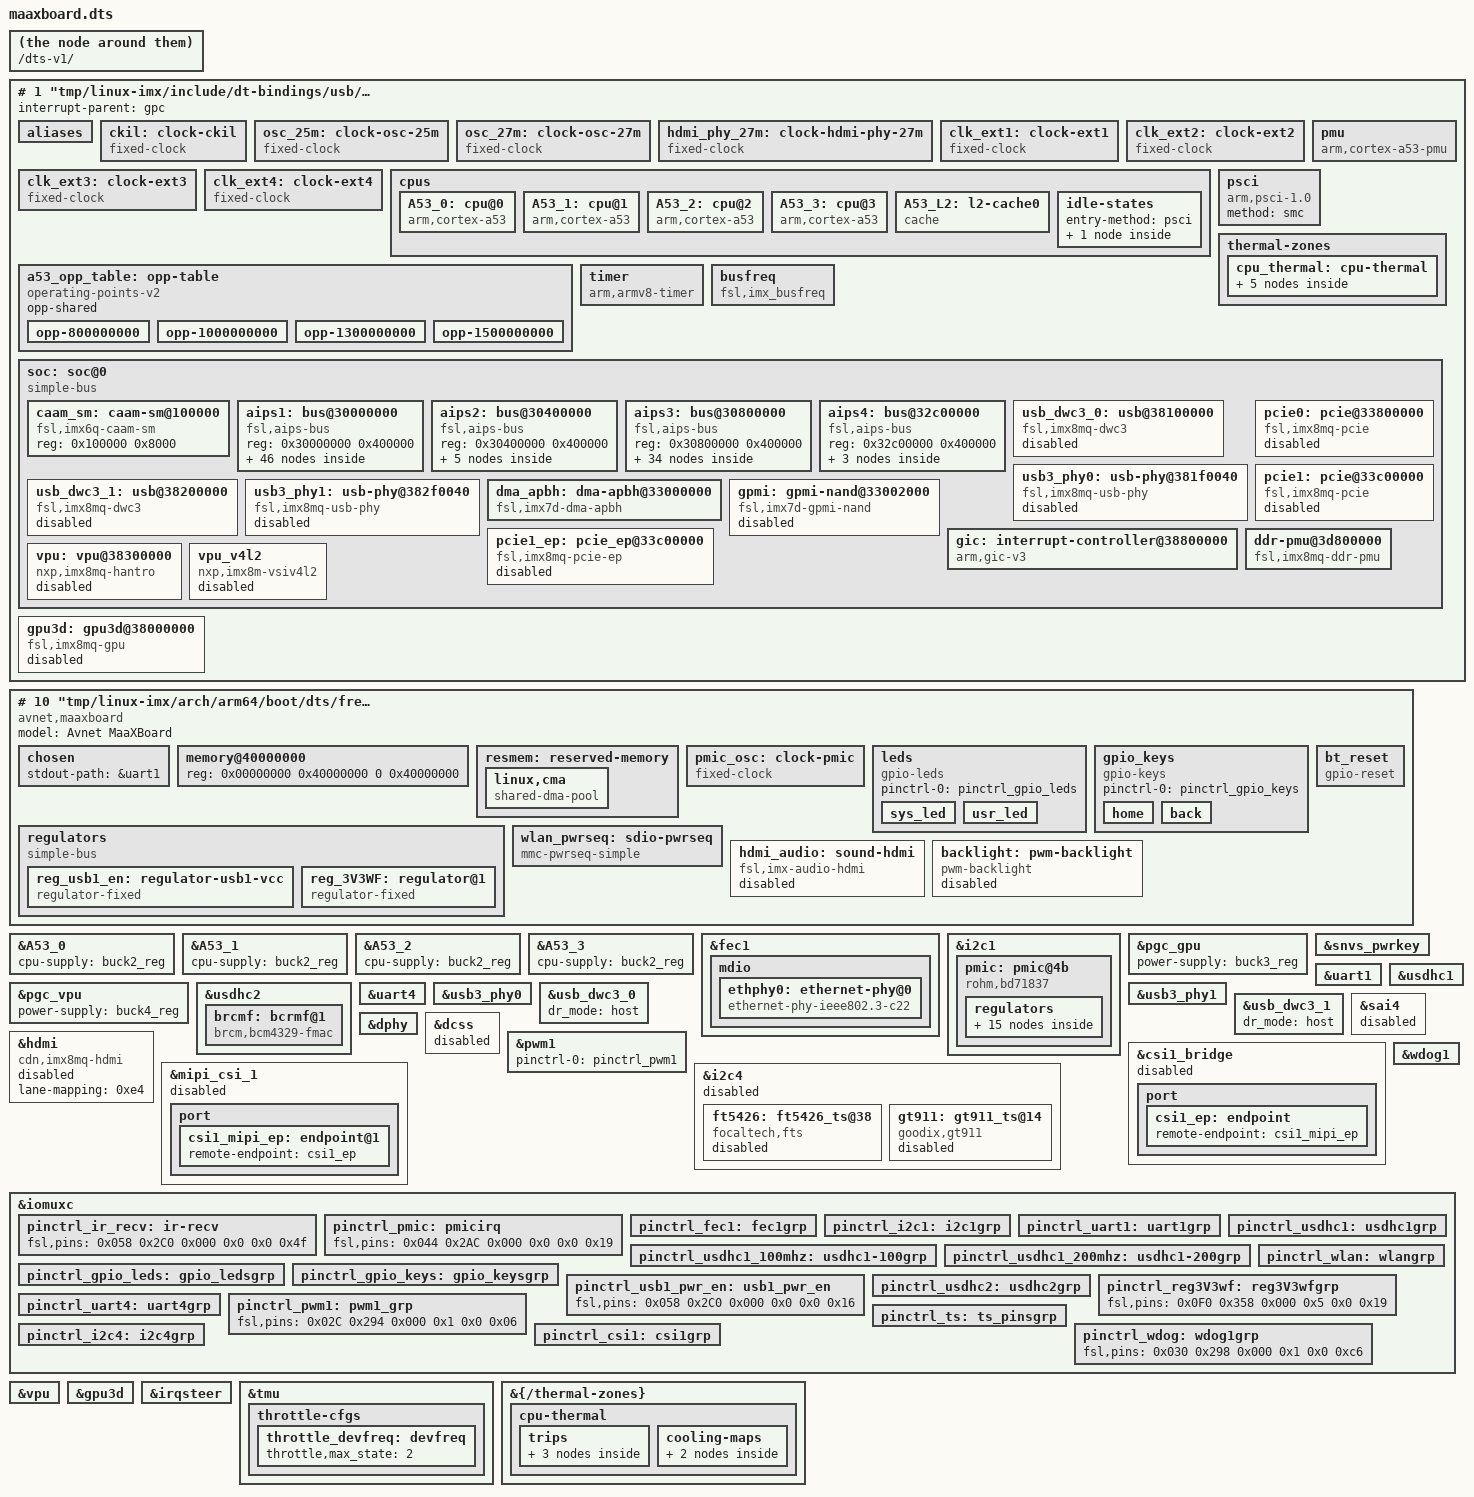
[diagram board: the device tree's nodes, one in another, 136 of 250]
# 0 "tmp/linux-imx/arch/arm64/boot/dts/freescale/maaxboard.dts"
# 0 "<built-in>"
# 0 "<command-line>"
# 1 "tmp/linux-imx/arch/arm64/boot/dts/freescale/maaxboard.dts"





/dts-v1/;

# 1 "tmp/linux-imx/include/dt-bindings/usb/pd.h" 1
# 9 "tmp/linux-imx/arch/arm64/boot/dts/freescale/maaxboard.dts" 2
# 1 "tmp/linux-imx/arch/arm64/boot/dts/freescale/imx8mq.dtsi" 1






# 1 "tmp/linux-imx/include/dt-bindings/clock/imx8mq-clock.h" 1
# 8 "tmp/linux-imx/arch/arm64/boot/dts/freescale/imx8mq.dtsi" 2
# 1 "tmp/linux-imx/include/dt-bindings/power/imx8mq-power.h" 1
# 9 "tmp/linux-imx/arch/arm64/boot/dts/freescale/imx8mq.dtsi" 2
# 1 "tmp/linux-imx/include/dt-bindings/reset/imx8mq-reset.h" 1
# 10 "tmp/linux-imx/arch/arm64/boot/dts/freescale/imx8mq.dtsi" 2
# 1 "tmp/linux-imx/include/dt-bindings/gpio/gpio.h" 1
# 11 "tmp/linux-imx/arch/arm64/boot/dts/freescale/imx8mq.dtsi" 2
# 1 "tmp/linux-imx/include/dt-bindings/input/input.h" 1
# 13 "tmp/linux-imx/include/dt-bindings/input/input.h"
# 1 "tmp/linux-imx/include/dt-bindings/input/linux-event-codes.h" 1
# 14 "tmp/linux-imx/include/dt-bindings/input/input.h" 2
# 12 "tmp/linux-imx/arch/arm64/boot/dts/freescale/imx8mq.dtsi" 2
# 1 "tmp/linux-imx/include/dt-bindings/interrupt-controller/arm-gic.h" 1
# 9 "tmp/linux-imx/include/dt-bindings/interrupt-controller/arm-gic.h"
# 1 "tmp/linux-imx/include/dt-bindings/interrupt-controller/irq.h" 1
# 10 "tmp/linux-imx/include/dt-bindings/interrupt-controller/arm-gic.h" 2
# 13 "tmp/linux-imx/arch/arm64/boot/dts/freescale/imx8mq.dtsi" 2
# 1 "tmp/linux-imx/include/dt-bindings/thermal/thermal.h" 1
# 14 "tmp/linux-imx/arch/arm64/boot/dts/freescale/imx8mq.dtsi" 2
# 1 "tmp/linux-imx/arch/arm64/boot/dts/freescale/imx8mq-pinfunc.h" 1
# 15 "tmp/linux-imx/arch/arm64/boot/dts/freescale/imx8mq.dtsi" 2

/ {
 interrupt-parent = <&gpc>;

 #address-cells = <2>;
 #size-cells = <2>;

 aliases {
  csi0 = &mipi_csi_1;
  csi1 = &mipi_csi_2;
  ethernet0 = &fec1;
  gpio0 = &gpio1;
  gpio1 = &gpio2;
  gpio2 = &gpio3;
  gpio3 = &gpio4;
  gpio4 = &gpio5;
  i2c0 = &i2c1;
  i2c1 = &i2c2;
  i2c2 = &i2c3;
  i2c3 = &i2c4;
  mmc0 = &usdhc1;
  mmc1 = &usdhc2;
  serial0 = &uart1;
  serial1 = &uart2;
  serial2 = &uart3;
  serial3 = &uart4;
  spi0 = &ecspi1;
  spi1 = &ecspi2;
  spi2 = &ecspi3;
 };

 ckil: clock-ckil {
  compatible = "fixed-clock";
  #clock-cells = <0>;
  clock-frequency = <32768>;
  clock-output-names = "ckil";
 };

 osc_25m: clock-osc-25m {
  compatible = "fixed-clock";
  #clock-cells = <0>;
  clock-frequency = <25000000>;
  clock-output-names = "osc_25m";
 };

 osc_27m: clock-osc-27m {
  compatible = "fixed-clock";
  #clock-cells = <0>;
  clock-frequency = <27000000>;
  clock-output-names = "osc_27m";
 };

 hdmi_phy_27m: clock-hdmi-phy-27m {
  compatible = "fixed-clock";
  #clock-cells = <0>;
  clock-frequency = <27000000>;
  clock-output-names = "hdmi_phy_27m";
 };

 clk_ext1: clock-ext1 {
  compatible = "fixed-clock";
  #clock-cells = <0>;
  clock-frequency = <133000000>;
  clock-output-names = "clk_ext1";
 };

 clk_ext2: clock-ext2 {
  compatible = "fixed-clock";
  #clock-cells = <0>;
  clock-frequency = <133000000>;
  clock-output-names = "clk_ext2";
 };

 clk_ext3: clock-ext3 {
  compatible = "fixed-clock";
  #clock-cells = <0>;
  clock-frequency = <133000000>;
  clock-output-names = "clk_ext3";
 };

 clk_ext4: clock-ext4 {
  compatible = "fixed-clock";
  #clock-cells = <0>;
  clock-frequency = <133000000>;
  clock-output-names = "clk_ext4";
 };

 cpus {
  #address-cells = <1>;
  #size-cells = <0>;

  A53_0: cpu@0 {
   device_type = "cpu";
   compatible = "arm,cortex-a53";
   reg = <0x0>;
   clock-latency = <61036>;
   clocks = <&clk 258>;
   enable-method = "psci";
   i-cache-size = <0x8000>;
   i-cache-line-size = <64>;
   i-cache-sets = <256>;
   d-cache-size = <0x8000>;
   d-cache-line-size = <64>;
   d-cache-sets = <128>;
   next-level-cache = <&A53_L2>;
   operating-points-v2 = <&a53_opp_table>;
   #cooling-cells = <2>;
   nvmem-cells = <&cpu_speed_grade>;
   nvmem-cell-names = "speed_grade";
   cpu-idle-states = <&CPU_SLEEP>;
  };

  A53_1: cpu@1 {
   device_type = "cpu";
   compatible = "arm,cortex-a53";
   reg = <0x1>;
   clock-latency = <61036>;
   clocks = <&clk 258>;
   enable-method = "psci";
   i-cache-size = <0x8000>;
   i-cache-line-size = <64>;
   i-cache-sets = <256>;
   d-cache-size = <0x8000>;
   d-cache-line-size = <64>;
   d-cache-sets = <128>;
   next-level-cache = <&A53_L2>;
   operating-points-v2 = <&a53_opp_table>;
   #cooling-cells = <2>;
   cpu-idle-states = <&CPU_SLEEP>;
  };

  A53_2: cpu@2 {
   device_type = "cpu";
   compatible = "arm,cortex-a53";
   reg = <0x2>;
   clock-latency = <61036>;
   clocks = <&clk 258>;
   enable-method = "psci";
   i-cache-size = <0x8000>;
   i-cache-line-size = <64>;
   i-cache-sets = <256>;
   d-cache-size = <0x8000>;
   d-cache-line-size = <64>;
   d-cache-sets = <128>;
   next-level-cache = <&A53_L2>;
   operating-points-v2 = <&a53_opp_table>;
   #cooling-cells = <2>;
   cpu-idle-states = <&CPU_SLEEP>;
  };

  A53_3: cpu@3 {
   device_type = "cpu";
   compatible = "arm,cortex-a53";
   reg = <0x3>;
   clock-latency = <61036>;
   clocks = <&clk 258>;
   enable-method = "psci";
   i-cache-size = <0x8000>;
   i-cache-line-size = <64>;
   i-cache-sets = <256>;
   d-cache-size = <0x8000>;
   d-cache-line-size = <64>;
   d-cache-sets = <128>;
   next-level-cache = <&A53_L2>;
   operating-points-v2 = <&a53_opp_table>;
   #cooling-cells = <2>;
   cpu-idle-states = <&CPU_SLEEP>;
  };

  A53_L2: l2-cache0 {
   compatible = "cache";
   cache-level = <2>;
   cache-size = <0x100000>;
   cache-line-size = <64>;
   cache-sets = <1024>;
  };

  idle-states {
   entry-method = "psci";

   CPU_SLEEP: cpu-sleep {
    compatible = "arm,idle-state";
    arm,psci-suspend-param = <0x0010033>;
    local-timer-stop;
    entry-latency-us = <1000>;
    exit-latency-us = <700>;
    min-residency-us = <2700>;
    wakeup-latency-us = <1500>;
   };
  };

 };

 a53_opp_table: opp-table {
  compatible = "operating-points-v2";
  opp-shared;

  opp-800000000 {
   opp-hz = /bits/ 64 <800000000>;
   opp-microvolt = <900000>;

   opp-supported-hw = <0xf>, <0x4>;
   clock-latency-ns = <150000>;
   opp-suspend;
  };

  opp-1000000000 {
   opp-hz = /bits/ 64 <1000000000>;
   opp-microvolt = <900000>;

   opp-supported-hw = <0xe>, <0x3>;
   clock-latency-ns = <150000>;
   opp-suspend;
  };

  opp-1300000000 {
   opp-hz = /bits/ 64 <1300000000>;
   opp-microvolt = <1000000>;
   opp-supported-hw = <0xc>, <0x4>;
   clock-latency-ns = <150000>;
   opp-suspend;
  };

  opp-1500000000 {
   opp-hz = /bits/ 64 <1500000000>;
   opp-microvolt = <1000000>;
   opp-supported-hw = <0x8>, <0x3>;
   clock-latency-ns = <150000>;
   opp-suspend;
  };
 };

 pmu {
  compatible = "arm,cortex-a53-pmu";
  interrupts = <1 7 4>;
  interrupt-parent = <&gic>;
 };

 psci {
  compatible = "arm,psci-1.0";
  method = "smc";
 };

 thermal-zones {
  cpu_thermal: cpu-thermal {
   polling-delay-passive = <250>;
   polling-delay = <2000>;
   thermal-sensors = <&tmu 0>;

   trips {
    cpu_alert: cpu-alert {
     temperature = <80000>;
     hysteresis = <2000>;
     type = "passive";
    };

    cpu-crit {
     temperature = <90000>;
     hysteresis = <2000>;
     type = "critical";
    };
   };

   cooling-maps {
    map0 {
     trip = <&cpu_alert>;
     cooling-device =
      <&A53_0 (~0) (~0)>,
      <&A53_1 (~0) (~0)>,
      <&A53_2 (~0) (~0)>,
      <&A53_3 (~0) (~0)>;
    };
   };
  };
 };

 timer {
  compatible = "arm,armv8-timer";
  interrupts = <1 13 8>,
               <1 14 8>,
               <1 11 8>,
               <1 10 8>;
  interrupt-parent = <&gic>;
  arm,no-tick-in-suspend;
 };

 busfreq {
  compatible = "fsl,imx_busfreq";
  clocks = <&clk 234>, <&clk 118>,
    <&clk 119>, <&clk 119>,
    <&clk 252>, <&clk 251>,
    <&clk 70>, <&clk 77>,
    <&clk 72>, <&clk 78>,
    <&clk 113>, <&clk 103>,
    <&clk 116>, <&clk 2>,
    <&clk 85>, <&clk 73>;
  clock-names = "dram_pll", "dram_alt_src", "dram_apb_src", "dram_apb_pre_div",
         "dram_core", "dram_alt_root", "sys1_pll_40m", "sys1_pll_400m",
         "sys1_pll_100m", "sys1_pll_800m", "noc_div", "main_axi_src",
         "ahb_div", "osc_25m", "sys2_pll_333m", "sys1_pll_133m";
  interrupts = <0 102 4>, <0 109 4>,
        <0 110 4>, <0 111 4>;
  interrupt-name = "irq_busfreq_0", "irq_busfreq_1", "irq_busfreq_2", "irq_busfreq_3";
 };

 soc: soc@0 {
  compatible = "simple-bus";
  #address-cells = <1>;
  #size-cells = <1>;
  ranges = <0x0 0x0 0x0 0x3e000000>;
  dma-ranges = <0x40000000 0x0 0x40000000 0xc0000000>;
  nvmem-cells = <&imx8mq_uid>;
  nvmem-cell-names = "soc_unique_id";

  caam_sm: caam-sm@100000 {
   compatible = "fsl,imx6q-caam-sm";
   reg = <0x100000 0x8000>;
  };

  aips1: bus@30000000 {
   compatible = "fsl,aips-bus", "simple-bus";
   reg = <0x30000000 0x400000>;
   #address-cells = <1>;
   #size-cells = <1>;
   ranges = <0x30000000 0x30000000 0x400000>;

   sai1: sai@30010000 {
    #sound-dai-cells = <0>;
    compatible = "fsl,imx8mq-sai",
          "fsl,imx6sx-sai";
    reg = <0x30010000 0x10000>;
    interrupts = <0 95 4>;
    clocks = <&clk 238>,
     <&clk 0>,
     <&clk 196>,
     <&clk 0>, <&clk 0>;
    clock-names = "bus", "mclk0", "mclk1", "mclk2", "mclk3";
    dmas = <&sdma2 8 1 0>, <&sdma2 9 1 0>;
    dma-names = "rx", "tx";
    fsl,dataline = <0 0xff 0xff>;
    status = "disabled";
   };

   sai6: sai@30030000 {
    #sound-dai-cells = <0>;
    compatible = "fsl,imx8mq-sai",
          "fsl,imx6sx-sai";
    reg = <0x30030000 0x10000>;
    interrupts = <0 90 4>;
    clocks = <&clk 243>,
     <&clk 0>,
     <&clk 201>,
     <&clk 0>, <&clk 0>;
    clock-names = "bus", "mclk0", "mclk1", "mclk2", "mclk3";
    dmas = <&sdma2 4 24 0>, <&sdma2 5 24 0>;
    dma-names = "rx", "tx";
    fsl,shared-interrupt;
    status = "disabled";
   };

   sai5: sai@30040000 {
    #sound-dai-cells = <0>;
    compatible = "fsl,imx8mq-sai",
          "fsl,imx6sx-sai";
    reg = <0x30040000 0x10000>;
    interrupts = <0 90 4>;
    clocks = <&clk 242>,
     <&clk 0>,
     <&clk 200>,
     <&clk 0>, <&clk 0>;
    clock-names = "bus", "mclk0", "mclk1", "mclk2", "mclk3";
    dmas = <&sdma2 2 24 0>, <&sdma2 3 24 0>;
    dma-names = "rx", "tx";
    fsl,shared-interrupt;
    fsl,dataline = <0 0xf 0xf>;
    status = "disabled";
   };

   sai4: sai@30050000 {
    #sound-dai-cells = <0>;
    compatible = "fsl,imx8mq-sai",
          "fsl,imx6sx-sai";
    reg = <0x30050000 0x10000>;
    interrupts = <0 100 4>;
    clocks = <&clk 241>,
     <&clk 0>,
     <&clk 199>,
     <&clk 0>, <&clk 0>;
    clock-names = "bus", "mclk0", "mclk1", "mclk2", "mclk3";
    dmas = <&sdma2 0 24 0>, <&sdma2 1 24 0>;
    dma-names = "rx", "tx";
    fsl,dataline = <0 0x0 0xf>;
    status = "disabled";
   };

   gpio1: gpio@30200000 {
    compatible = "fsl,imx8mq-gpio", "fsl,imx35-gpio";
    reg = <0x30200000 0x10000>;
    interrupts = <0 64 4>,
                 <0 65 4>;
    clocks = <&clk 259>;
    gpio-controller;
    #gpio-cells = <2>;
    interrupt-controller;
    #interrupt-cells = <2>;
    gpio-ranges = <&iomuxc 0 10 30>;
   };

   gpio2: gpio@30210000 {
    compatible = "fsl,imx8mq-gpio", "fsl,imx35-gpio";
    reg = <0x30210000 0x10000>;
    interrupts = <0 66 4>,
                 <0 67 4>;
    clocks = <&clk 260>;
    gpio-controller;
    #gpio-cells = <2>;
    interrupt-controller;
    #interrupt-cells = <2>;
    gpio-ranges = <&iomuxc 0 40 21>;
   };

   gpio3: gpio@30220000 {
    compatible = "fsl,imx8mq-gpio", "fsl,imx35-gpio";
    reg = <0x30220000 0x10000>;
    interrupts = <0 68 4>,
                 <0 69 4>;
    clocks = <&clk 261>;
    gpio-controller;
    #gpio-cells = <2>;
    interrupt-controller;
    #interrupt-cells = <2>;
    gpio-ranges = <&iomuxc 0 61 26>;
   };

   gpio4: gpio@30230000 {
    compatible = "fsl,imx8mq-gpio", "fsl,imx35-gpio";
    reg = <0x30230000 0x10000>;
    interrupts = <0 70 4>,
                 <0 71 4>;
    clocks = <&clk 262>;
    gpio-controller;
    #gpio-cells = <2>;
    interrupt-controller;
    #interrupt-cells = <2>;
    gpio-ranges = <&iomuxc 0 87 32>;
   };

   gpio5: gpio@30240000 {
    compatible = "fsl,imx8mq-gpio", "fsl,imx35-gpio";
    reg = <0x30240000 0x10000>;
    interrupts = <0 72 4>,
                 <0 73 4>;
    clocks = <&clk 263>;
    gpio-controller;
    #gpio-cells = <2>;
    interrupt-controller;
    #interrupt-cells = <2>;
    gpio-ranges = <&iomuxc 0 119 30>;
   };

   tmu: tmu@30260000 {
    compatible = "fsl,imx8mq-tmu";
    reg = <0x30260000 0x10000>;
    interrupts = <0 49 4>;
    clocks = <&clk 246>;
    little-endian;
    fsl,tmu-range = <0xb0000 0xa0026 0x80048 0x70061>;
    fsl,tmu-calibration = <0x00000000 0x00000023>,
            <0x00000001 0x00000029>,
            <0x00000002 0x0000002f>,
            <0x00000003 0x00000035>,
            <0x00000004 0x0000003d>,
            <0x00000005 0x00000043>,
            <0x00000006 0x0000004b>,
            <0x00000007 0x00000051>,
            <0x00000008 0x00000057>,
            <0x00000009 0x0000005f>,
            <0x0000000a 0x00000067>,
            <0x0000000b 0x0000006f>,

            <0x00010000 0x0000001b>,
            <0x00010001 0x00000023>,
            <0x00010002 0x0000002b>,
            <0x00010003 0x00000033>,
            <0x00010004 0x0000003b>,
            <0x00010005 0x00000043>,
            <0x00010006 0x0000004b>,
            <0x00010007 0x00000055>,
            <0x00010008 0x0000005d>,
            <0x00010009 0x00000067>,
            <0x0001000a 0x00000070>,

            <0x00020000 0x00000017>,
            <0x00020001 0x00000023>,
            <0x00020002 0x0000002d>,
            <0x00020003 0x00000037>,
            <0x00020004 0x00000041>,
            <0x00020005 0x0000004b>,
            <0x00020006 0x00000057>,
            <0x00020007 0x00000063>,
            <0x00020008 0x0000006f>,

            <0x00030000 0x00000015>,
            <0x00030001 0x00000021>,
            <0x00030002 0x0000002d>,
            <0x00030003 0x00000039>,
            <0x00030004 0x00000045>,
            <0x00030005 0x00000053>,
            <0x00030006 0x0000005f>,
            <0x00030007 0x00000071>;
    #thermal-sensor-cells = <1>;
   };

   wdog1: watchdog@30280000 {
    compatible = "fsl,imx8mq-wdt", "fsl,imx21-wdt";
    reg = <0x30280000 0x10000>;
    interrupts = <0 78 4>;
    clocks = <&clk 212>;
    status = "disabled";
   };

   wdog2: watchdog@30290000 {
    compatible = "fsl,imx8mq-wdt", "fsl,imx21-wdt";
    reg = <0x30290000 0x10000>;
    interrupts = <0 79 4>;
    clocks = <&clk 213>;
    status = "disabled";
   };

   wdog3: watchdog@302a0000 {
    compatible = "fsl,imx8mq-wdt", "fsl,imx21-wdt";
    reg = <0x302a0000 0x10000>;
    interrupts = <0 10 4>;
    clocks = <&clk 214>;
    status = "disabled";
   };

   sdma2: dma-controller@302c0000 {
    compatible = "fsl,imx8mq-sdma","fsl,imx7d-sdma";
    reg = <0x302c0000 0x10000>;
    interrupts = <0 103 4>;
    clocks = <&clk 228>,
      <&clk 228>;
    clock-names = "ipg", "ahb";
    #dma-cells = <3>;
    fsl,sdma-ram-script-name = "imx/sdma/sdma-imx7d.bin";
   };

   lcdif: lcd-controller@30320000 {
    compatible = "fsl,imx8mq-lcdif", "fsl,imx28-lcdif";
    reg = <0x30320000 0x10000>;
    interrupts = <0 5 4>;
    clocks = <&clk 128>;
    clock-names = "pix";
    assigned-clocks = <&clk 33>,
        <&clk 36>,
        <&clk 128>,
        <&clk 35>;
    assigned-clock-parents = <&clk 2>,
        <&clk 35>,
        <&clk 37>;
    assigned-clock-rates = <0>, <0>, <0>, <594000000>;
    status = "disabled";

    port {
     lcdif_mipi_dsi: endpoint {
      remote-endpoint = <&mipi_dsi_lcdif_in>;
     };
    };
   };

   iomuxc: pinctrl@30330000 {
    compatible = "fsl,imx8mq-iomuxc";
    reg = <0x30330000 0x10000>;
   };

   iomuxc_gpr: syscon@30340000 {
    compatible = "fsl,imx8mq-iomuxc-gpr", "fsl,imx6q-iomuxc-gpr",
          "syscon", "simple-mfd";
    reg = <0x30340000 0x10000>;

    mux: mux-controller {
     compatible = "mmio-mux";
     #mux-control-cells = <1>;
     mux-reg-masks = <0x34 0x00000004>;
    };
   };

   ocotp: efuse@30350000 {
    compatible = "fsl,imx8mq-ocotp", "syscon", "simple-mfd";
    reg = <0x30350000 0x10000>;
    clocks = <&clk 250>;
    #address-cells = <1>;
    #size-cells = <1>;

    imx8mq_uid: soc-uid@4 {
     reg = <0x4 0x8>;
    };

    cpu_speed_grade: speed-grade@10 {
     reg = <0x10 4>;
    };

    fec_mac_address: mac-address@90 {
     reg = <0x90 6>;
    };

    imx8mq_soc: imx8mq-soc {
     compatible = "fsl,imx8mq-soc";
     nvmem-cells = <&imx8mq_uid>;
     nvmem-cell-names = "soc_unique_id";
    };
   };

   anatop: syscon@30360000 {
    compatible = "fsl,imx8mq-anatop", "syscon";
    reg = <0x30360000 0x10000>;
    interrupts = <0 49 4>;
   };

   irq_sec_vio: caam_secvio {
    compatible = "fsl,imx6q-caam-secvio";
    interrupts = <0 20 4>;
    jtag-tamper = "disabled";
    watchdog-tamper = "enabled";
    internal-boot-tamper = "enabled";
    external-pin-tamper = "disabled";
   };

   caam_snvs: caam-snvs@30370000 {
    compatible = "fsl,imx6q-caam-snvs";
    reg = <0x30370000 0x10000>;
    clocks = <&clk 264>;
    clock-names = "ipg";
   };

   snvs: snvs@30370000 {
    compatible = "fsl,sec-v4.0-mon", "syscon", "simple-mfd";
    reg = <0x30370000 0x10000>;

    snvs_rtc: snvs-rtc-lp{
     compatible = "fsl,sec-v4.0-mon-rtc-lp";
     regmap =<&snvs>;
     offset = <0x34>;
     interrupts = <0 19 4>,
      <0 20 4>;
     clocks = <&clk 264>;
     clock-names = "snvs-rtc";
    };

    snvs_pwrkey: snvs-powerkey {
     compatible = "fsl,sec-v4.0-pwrkey";
     regmap = <&snvs>;
     interrupts = <0 4 4>;
     clocks = <&clk 264>;
     clock-names = "snvs-pwrkey";
     linux,keycode = <116>;
     wakeup-source;
     status = "disabled";
    };
   };

   clk: clock-controller@30380000 {
    compatible = "fsl,imx8mq-ccm";
    reg = <0x30380000 0x10000>;
    interrupts = <0 85 4>,
                 <0 86 4>;
    #clock-cells = <1>;
    clocks = <&ckil>, <&osc_25m>, <&osc_27m>,
             <&clk_ext1>, <&clk_ext2>,
             <&clk_ext3>, <&clk_ext4>;
    clock-names = "ckil", "osc_25m", "osc_27m",
                  "clk_ext1", "clk_ext2",
                  "clk_ext3", "clk_ext4";
    assigned-clocks = <&clk 88>,
        <&clk 289>,
        <&clk 113>,
        <&clk 117>,
        <&clk 26>,
        <&clk 31>,
        <&clk 25>,
        <&clk 30>,
        <&clk 105>;
    assigned-clock-rates = <0>, <0>,
             <800000000>,
             <0>,
             <0>,
             <0>,
             <786432000>,
             <722534400>,
             <0>;
    assigned-clock-parents = <&clk 78>,
        <&clk 12>,
        <&clk 78>,
        <&clk 86>,
        <&clk 25>,
        <&clk 30>,
        <0>,
               <0>,
        <&clk 76>;
   };

   src: reset-controller@30390000 {
    compatible = "fsl,imx8mq-src", "syscon";
    reg = <0x30390000 0x10000>;
    interrupts = <0 89 4>;
    #reset-cells = <1>;
   };

   gpc: gpc@303a0000 {
    compatible = "fsl,imx8mq-gpc";
    reg = <0x303a0000 0x10000>;
    interrupts = <0 87 4>;
    interrupt-parent = <&gic>;
    interrupt-controller;
    broken-wake-request-signals;
    #interrupt-cells = <3>;

    pgc {
     #address-cells = <1>;
     #size-cells = <0>;

     pgc_mipi: power-domain@0 {
      #power-domain-cells = <0>;
      reg = <0>;
     };
# 757 "tmp/linux-imx/arch/arm64/boot/dts/freescale/imx8mq.dtsi"
     pgc_pcie: power-domain@1 {
      #power-domain-cells = <0>;
      reg = <1>;
      power-domains = <&pgc_pcie2>;
     };

     pgc_otg1: power-domain@2 {
      #power-domain-cells = <0>;
      reg = <2>;
     };

     pgc_otg2: power-domain@3 {
      #power-domain-cells = <0>;
      reg = <3>;
     };

     pgc_ddr1: power-domain@4 {
      #power-domain-cells = <0>;
      reg = <4>;
     };

     pgc_gpu: power-domain@5 {
      #power-domain-cells = <0>;
      reg = <5>;
      clocks = <&clk 215>,
               <&clk 102>,
        <&clk 111>,
               <&clk 112>;
     };

     pgc_vpu: power-domain@6 {
      #power-domain-cells = <0>;
      reg = <6>;
      clocks = <&clk 223>,
        <&clk 229>,
        <&clk 230>;
      assigned-clocks = <&clk 120>,
          <&clk 121>,
          <&clk 106>,
          <&clk 21>;
      assigned-clock-parents = <&clk 22>,
          <&clk 22>,
          <&clk 78>,
          <&clk 20>;
      assigned-clock-rates = <600000000>,
               <600000000>,
               <800000000>,
               <0>;
     };

     pgc_disp: power-domain@7 {
      #power-domain-cells = <0>;
      reg = <7>;
     };

     pgc_mipi_csi1: power-domain@8 {
      #power-domain-cells = <0>;
      reg = <8>;
     };

     pgc_mipi_csi2: power-domain@9 {
      #power-domain-cells = <0>;
      reg = <9>;
     };

     pgc_pcie2: power-domain@a {
      #power-domain-cells = <0>;
      reg = <10>;
     };
    };
   };
  };

  aips2: bus@30400000 {
   compatible = "fsl,aips-bus", "simple-bus";
   reg = <0x30400000 0x400000>;
   #address-cells = <1>;
   #size-cells = <1>;
   ranges = <0x30400000 0x30400000 0x400000>;

   pwm1: pwm@30660000 {
    compatible = "fsl,imx8mq-pwm", "fsl,imx27-pwm";
    reg = <0x30660000 0x10000>;
    interrupts = <0 81 4>;
    clocks = <&clk 191>,
             <&clk 191>;
    clock-names = "ipg", "per";
    #pwm-cells = <3>;
    status = "disabled";
   };

   pwm2: pwm@30670000 {
    compatible = "fsl,imx8mq-pwm", "fsl,imx27-pwm";
    reg = <0x30670000 0x10000>;
    interrupts = <0 82 4>;
    clocks = <&clk 192>,
             <&clk 192>;
    clock-names = "ipg", "per";
    #pwm-cells = <3>;
    status = "disabled";
   };

   pwm3: pwm@30680000 {
    compatible = "fsl,imx8mq-pwm", "fsl,imx27-pwm";
    reg = <0x30680000 0x10000>;
    interrupts = <0 83 4>;
    clocks = <&clk 193>,
             <&clk 193>;
    clock-names = "ipg", "per";
    #pwm-cells = <3>;
    status = "disabled";
   };

   pwm4: pwm@30690000 {
    compatible = "fsl,imx8mq-pwm", "fsl,imx27-pwm";
    reg = <0x30690000 0x10000>;
    interrupts = <0 84 4>;
    clocks = <&clk 194>,
             <&clk 194>;
    clock-names = "ipg", "per";
    #pwm-cells = <3>;
    status = "disabled";
   };

   system_counter: timer@306a0000 {
    compatible = "nxp,sysctr-timer";
    reg = <0x306a0000 0x20000>;
    interrupts = <0 47 4>;
    clocks = <&osc_25m>;
    clock-names = "per";
   };
  };

  aips3: bus@30800000 {
   compatible = "fsl,aips-bus", "simple-bus";
   reg = <0x30800000 0x400000>;
   #address-cells = <1>;
   #size-cells = <1>;
   ranges = <0x30800000 0x30800000 0x400000>,
     <0x08000000 0x08000000 0x10000000>;

   spdif1: spdif@30810000 {
    compatible = "fsl,imx8mm-spdif", "fsl,imx35-spdif";
    reg = <0x30810000 0x10000>;
    interrupts = <0 6 4>;
    clocks = <&clk 236>,
     <&clk 2>,
     <&clk 135>,
     <&clk 0>,
     <&clk 0>,
     <&clk 0>,
     <&clk 236>,
     <&clk 0>,
     <&clk 0>,
     <&clk 0>;
    clock-names = "core", "rxtx0",
           "rxtx1", "rxtx2",
           "rxtx3", "rxtx4",
           "rxtx5", "rxtx6",
           "rxtx7", "spba";
    dmas = <&sdma1 8 18 0>, <&sdma1 9 18 0>;
    dma-names = "rx", "tx";
    status = "disabled";
   };

   ecspi1: spi@30820000 {
    #address-cells = <1>;
    #size-cells = <0>;
    compatible = "fsl,imx8mq-ecspi", "fsl,imx51-ecspi";
    reg = <0x30820000 0x10000>;
    interrupts = <0 31 4>;
    clocks = <&clk 179>,
      <&clk 179>;
    clock-names = "ipg", "per";
    dmas = <&sdma1 0 7 1>, <&sdma1 1 7 2>;
    dma-names = "rx", "tx";
    status = "disabled";
   };

   ecspi2: spi@30830000 {
    #address-cells = <1>;
    #size-cells = <0>;
    compatible = "fsl,imx8mq-ecspi", "fsl,imx51-ecspi";
    reg = <0x30830000 0x10000>;
    interrupts = <0 32 4>;
    clocks = <&clk 180>,
      <&clk 180>;
    clock-names = "ipg", "per";
    dmas = <&sdma1 2 7 1>, <&sdma1 3 7 2>;
    dma-names = "rx", "tx";
    status = "disabled";
   };

   ecspi3: spi@30840000 {
    #address-cells = <1>;
    #size-cells = <0>;
    compatible = "fsl,imx8mq-ecspi", "fsl,imx51-ecspi";
    reg = <0x30840000 0x10000>;
    interrupts = <0 33 4>;
    clocks = <&clk 181>,
      <&clk 181>;
    clock-names = "ipg", "per";
    dmas = <&sdma1 4 7 1>, <&sdma1 5 7 2>;
    dma-names = "rx", "tx";
    status = "disabled";
   };

   uart1: serial@30860000 {
    compatible = "fsl,imx8mq-uart",
                 "fsl,imx6q-uart";
    reg = <0x30860000 0x10000>;
    interrupts = <0 26 4>;
    clocks = <&clk 202>,
             <&clk 202>;
    clock-names = "ipg", "per";
    status = "disabled";
   };

   uart3: serial@30880000 {
    compatible = "fsl,imx8mq-uart",
                 "fsl,imx6q-uart";
    reg = <0x30880000 0x10000>;
    interrupts = <0 28 4>;
    clocks = <&clk 204>,
             <&clk 204>;
    clock-names = "ipg", "per";
    dmas = <&sdma1 26 4 0>, <&sdma1 27 4 0>;
    dma-names = "rx", "tx";
    status = "disabled";
   };

   uart2: serial@30890000 {
    compatible = "fsl,imx8mq-uart",
                 "fsl,imx6q-uart";
    reg = <0x30890000 0x10000>;
    interrupts = <0 27 4>;
    clocks = <&clk 203>,
             <&clk 203>;
    clock-names = "ipg", "per";
    dmas = <&sdma1 24 4 0>, <&sdma1 25 4 0>;
    dma-names = "rx", "tx";
    status = "disabled";
   };

   spdif2: spdif@308a0000 {
    compatible = "fsl,imx8mm-spdif", "fsl,imx35-spdif";
    reg = <0x308a0000 0x10000>;
    interrupts = <0 13 4>;
    clocks = <&clk 236>,
     <&clk 2>,
     <&clk 136>,
     <&clk 0>,
     <&clk 0>,
     <&clk 0>,
     <&clk 236>,
     <&clk 0>,
     <&clk 0>,
     <&clk 0>;
    clock-names = "core", "rxtx0",
           "rxtx1", "rxtx2",
           "rxtx3", "rxtx4",
           "rxtx5", "rxtx6",
           "rxtx7", "spba";
    dmas = <&sdma1 16 18 0>, <&sdma1 17 18 0>;
    dma-names = "rx", "tx";
    status = "disabled";
   };

   sai2: sai@308b0000 {
    #sound-dai-cells = <0>;
    compatible = "fsl,imx8mq-sai";
    reg = <0x308b0000 0x10000>;
    interrupts = <0 96 4>;
    clocks = <&clk 239>,
      <&clk 0>,
      <&clk 197>,
      <&clk 0>, <&clk 0>;
    clock-names = "bus", "mclk0", "mclk1", "mclk2", "mclk3";
    dmas = <&sdma1 10 24 0>, <&sdma1 11 24 0>;
    dma-names = "rx", "tx";
    status = "disabled";
   };

   sai3: sai@308c0000 {
    #sound-dai-cells = <0>;
    compatible = "fsl,imx8mq-sai",
          "fsl,imx6sx-sai";
    reg = <0x308c0000 0x10000>;
    interrupts = <0 50 4>;
    clocks = <&clk 240>,
     <&clk 0>,
     <&clk 198>,
     <&clk 0>, <&clk 0>;
    clock-names = "bus", "mclk0", "mclk1", "mclk2", "mclk3";
    dmas = <&sdma1 12 24 0>, <&sdma1 13 24 0>;
    dma-names = "rx", "tx";
    status = "disabled";
   };

   crypto: crypto@30900000 {
    compatible = "fsl,sec-v4.0";
    #address-cells = <1>;
    #size-cells = <1>;
    reg = <0x30900000 0x40000>;
    ranges = <0 0x30900000 0x40000>;
    interrupts = <0 91 4>;
    clocks = <&clk 116>,
      <&clk 236>;
    clock-names = "aclk", "ipg";

    sec_jr0: jr@1000 {
     compatible = "fsl,sec-v4.0-job-ring";
     reg = <0x1000 0x1000>;
     interrupts = <0 105 4>;
     status = "disabled";
    };

    sec_jr1: jr@2000 {
     compatible = "fsl,sec-v4.0-job-ring";
     reg = <0x2000 0x1000>;
     interrupts = <0 106 4>;
    };

    sec_jr2: jr@3000 {
     compatible = "fsl,sec-v4.0-job-ring";
     reg = <0x3000 0x1000>;
     interrupts = <0 114 4>;
    };
   };

   mipi_dsi: mipi-dsi@30a00000 {
    compatible = "fsl,imx8mq-nwl-dsi";
    reg = <0x30a00000 0x300>;
    clocks = <&clk 163>,
      <&clk 244>,
      <&clk 245>,
      <&clk 164>,
      <&clk 35>,
      <&clk 128>;
    clock-names = "core", "rx_esc", "tx_esc", "phy_ref", "video_pll", "lcdif";
    assigned-clocks = <&clk 164>,
        <&clk 163>,
        <&clk 244>,
        <&clk 245>;
    assigned-clock-parents = <&clk 37>,
        <&clk 76>,
        <&clk 71>;
    assigned-clock-rates = <27000000>,
             <266000000>,
             <80000000>,
             <20000000>;
    interrupts = <0 34 4>;
    mux-controls = <&mux 0>;
    power-domains = <&pgc_mipi>;
    phys = <&dphy>;
    phy-names = "dphy";
    resets = <&src 21>,
      <&src 23>,
      <&src 24>,
      <&src 25>;
    reset-names = "byte", "dpi", "esc", "pclk";
    status = "disabled";

    ports {
     #address-cells = <1>;
     #size-cells = <0>;

     port@0 {
      reg = <0>;
      #address-cells = <1>;
      #size-cells = <0>;
      mipi_dsi_lcdif_in: endpoint@0 {
       reg = <0>;
       remote-endpoint = <&lcdif_mipi_dsi>;
      };
     };
    };
   };

   dphy: dphy@30a00300 {
    compatible = "fsl,imx8mq-mipi-dphy";
    reg = <0x30a00300 0x100>;
    clocks = <&clk 164>;
    clock-names = "phy_ref";
    assigned-clocks = <&clk 33>,
        <&clk 36>,
        <&clk 164>,
        <&clk 35>;
    assigned-clock-parents = <&clk 2>,
        <&clk 35>,
        <&clk 37>;
    assigned-clock-rates = <0>, <0>, <24000000>, <594000000>;
    #phy-cells = <0>;
    power-domains = <&pgc_mipi>;
    status = "disabled";
   };

   i2c1: i2c@30a20000 {
    compatible = "fsl,imx8mq-i2c", "fsl,imx21-i2c";
    reg = <0x30a20000 0x10000>;
    interrupts = <0 35 4>;
    clocks = <&clk 184>;
    #address-cells = <1>;
    #size-cells = <0>;
    status = "disabled";
   };

   i2c2: i2c@30a30000 {
    compatible = "fsl,imx8mq-i2c", "fsl,imx21-i2c";
    reg = <0x30a30000 0x10000>;
    interrupts = <0 36 4>;
    clocks = <&clk 185>;
    #address-cells = <1>;
    #size-cells = <0>;
    status = "disabled";
   };

   i2c3: i2c@30a40000 {
    compatible = "fsl,imx8mq-i2c", "fsl,imx21-i2c";
    reg = <0x30a40000 0x10000>;
    interrupts = <0 37 4>;
    clocks = <&clk 186>;
    #address-cells = <1>;
    #size-cells = <0>;
    status = "disabled";
   };

   i2c4: i2c@30a50000 {
    compatible = "fsl,imx8mq-i2c", "fsl,imx21-i2c";
    reg = <0x30a50000 0x10000>;
    interrupts = <0 38 4>;
    clocks = <&clk 187>;
    #address-cells = <1>;
    #size-cells = <0>;
    status = "disabled";
   };

   uart4: serial@30a60000 {
    compatible = "fsl,imx8mq-uart",
                 "fsl,imx6q-uart";
    reg = <0x30a60000 0x10000>;
    interrupts = <0 29 4>;
    clocks = <&clk 205>,
             <&clk 205>;
    clock-names = "ipg", "per";
    dmas = <&sdma1 28 4 0>, <&sdma1 29 4 0>;
    dma-names = "rx", "tx";
    status = "disabled";
   };

   mipi_csi_1: mipi_csi1@30a70000 {
    compatible = "fsl,mxc-mipi-csi2_yav";
    reg = <0x30a70000 0x1000>;
    interrupts = <0 44 4>;
    clocks = <&clk 167>,
      <&clk 169>,
      <&clk 168>;
    clock-names = "clk_core", "clk_esc", "clk_pxl";
    assigned-clocks = <&clk 167>,
        <&clk 168>,
        <&clk 169>;
    assigned-clock-rates = <133000000>, <100000000>, <66000000>;
    power-domains = <&pgc_mipi_csi1>;
    csis-phy-reset = <&src 0x4c 7>;
    phy-gpr = <&iomuxc_gpr 0x88>;
    status = "disabled";
   };

   csi1_bridge: csi1_bridge@30a90000 {
    compatible = "fsl,imx8mq-csi", "fsl,imx6s-csi";
    reg = <0x30a90000 0x10000>;
    interrupts = <0 42 4>;
    clocks = <&clk 0>,
     <&clk 224>,
     <&clk 0>;
    clock-names = "disp-axi", "csi_mclk", "disp_dcic";
    status = "disabled";
   };

   mu: mailbox@30aa0000 {
    compatible = "fsl,imx8mq-mu", "fsl,imx6sx-mu";
    reg = <0x30aa0000 0x10000>;
    interrupts = <0 88 4>;
    clocks = <&clk 253>;
    #mbox-cells = <2>;
   };

   usdhc1: mmc@30b40000 {
    compatible = "fsl,imx8mq-usdhc",
                 "fsl,imx7d-usdhc";
    reg = <0x30b40000 0x10000>;
    interrupts = <0 22 4>;
    clocks = <&clk 236>,
             <&clk 105>,
             <&clk 210>;
    clock-names = "ipg", "ahb", "per";
    fsl,tuning-start-tap = <20>;
    fsl,tuning-step = <2>;
    bus-width = <4>;
    status = "disabled";
   };

   usdhc2: mmc@30b50000 {
    compatible = "fsl,imx8mq-usdhc",
                 "fsl,imx7d-usdhc";
    reg = <0x30b50000 0x10000>;
    interrupts = <0 23 4>;
    clocks = <&clk 236>,
             <&clk 105>,
             <&clk 211>;
    clock-names = "ipg", "ahb", "per";
    fsl,tuning-start-tap = <20>;
    fsl,tuning-step = <2>;
    bus-width = <4>;
    status = "disabled";
   };

   mipi_csi_2: mipi_csi2@30b60000 {
    compatible = "fsl,mxc-mipi-csi2_yav";
    reg = <0x30b60000 0x1000>;
    interrupts = <0 45 4>;
    clocks = <&clk 170>,
      <&clk 172>,
      <&clk 171>;
    clock-names = "clk_core", "clk_esc", "clk_pxl";
    assigned-clocks = <&clk 170>,
        <&clk 171>,
        <&clk 172>;
    assigned-clock-rates = <133000000>, <100000000>, <66000000>;
    power-domains = <&pgc_mipi_csi2>;
    csis-phy-reset = <&src 0x50 7>;
    phy-gpr = <&iomuxc_gpr 0xa4>;
    status = "disabled";
   };

   csi2_bridge: csi2_bridge@30b80000 {
    compatible = "fsl,imx8mq-csi", "fsl,imx6s-csi";
    reg = <0x30b80000 0x10000>;
    interrupts = <0 43 4>;
    clocks = <&clk 0>,
     <&clk 225>,
     <&clk 0>;
    clock-names = "disp-axi", "csi_mclk", "disp_dcic";
    status = "disabled";
   };

   qspi0: spi@30bb0000 {
    #address-cells = <1>;
    #size-cells = <0>;
    compatible = "fsl,imx8mq-qspi", "fsl,imx7d-qspi";
    reg = <0x30bb0000 0x10000>,
          <0x08000000 0x10000000>;
    reg-names = "QuadSPI", "QuadSPI-memory";
    interrupts = <0 107 4>;
    clocks = <&clk 195>,
      <&clk 195>;
    clock-names = "qspi_en", "qspi";
    status = "disabled";
   };

   sdma1: dma-controller@30bd0000 {
    compatible = "fsl,imx8mq-sdma","fsl,imx7d-sdma";
    reg = <0x30bd0000 0x10000>;
    interrupts = <0 2 4>;
    clocks = <&clk 227>,
      <&clk 116>;
    clock-names = "ipg", "ahb";
    #dma-cells = <3>;
    fsl,sdma-ram-script-name = "imx/sdma/sdma-imx7d.bin";
   };

   fec1: ethernet@30be0000 {
    compatible = "fsl,imx8mq-fec", "fsl,imx6sx-fec";
    reg = <0x30be0000 0x10000>;
    interrupts = <0 118 4>,
                 <0 119 4>,
          <0 120 4>,
          <0 121 4>;
    clocks = <&clk 182>,
             <&clk 182>,
             <&clk 138>,
             <&clk 137>,
             <&clk 139>;
    clock-names = "ipg", "ahb", "ptp",
                  "enet_clk_ref", "enet_out";
    assigned-clocks = <&clk 104>,
        <&clk 138>,
        <&clk 137>,
        <&clk 139>;
    assigned-clock-parents = <&clk 76>,
        <&clk 80>,
        <&clk 81>,
        <&clk 79>;
    assigned-clock-rates = <0>, <100000000>, <125000000>, <0>;
    fsl,num-tx-queues = <3>;
    fsl,num-rx-queues = <3>;
    nvmem-cells = <&fec_mac_address>;
    nvmem-cell-names = "mac-address";
    fsl,stop-mode = <&iomuxc_gpr 0x10 3>;
    status = "disabled";
   };
  };

  aips4: bus@32c00000 {
   compatible = "fsl,aips-bus", "simple-bus";
   reg = <0x32c00000 0x400000>;
   #address-cells = <1>;
   #size-cells = <1>;
   ranges = <0x32c00000 0x32c00000 0x400000>;

   hdmi: hdmi@32c00000 {
    reg = <0x32c00000 0x100000>,
     <0x32e40000 0x40000>;
    interrupts = <0 16 4>,
        <0 25 4>;
    interrupt-names = "plug_in", "plug_out";
   };

   irqsteer: interrupt-controller@32e2d000 {
    compatible = "fsl,imx8m-irqsteer", "fsl,imx-irqsteer";
    reg = <0x32e2d000 0x1000>;
    interrupts = <0 18 4>;
    clocks = <&clk 248>;
    clock-names = "ipg";
    fsl,channel = <0>;
    fsl,num-irqs = <64>;
    interrupt-controller;
    #interrupt-cells = <1>;
   };

   dcss: display-controller@32e00000 {
    #address-cells = <1>;
    #size-cells = <0>;
    compatible = "nxp,imx8mq-dcss";
    reg = <0x32e00000 0x2d000>, <0x32e2f000 0x1000>;
    interrupts = <6>, <8>, <9>, <16>, <17>;
    interrupt-names = "ctxld", "ctxld_kick", "vblank",
          "dtrc_ch1", "dtrc_ch2";
    interrupt-parent = <&irqsteer>;
    clocks = <&clk 248>,
      <&clk 247>,
      <&clk 249>,
      <&clk 254>,
      <&clk 122>,
      <&clk 266>,
      <&hdmi_phy_27m>;
    clock-names = "apb", "axi", "rtrm", "pix", "dtrc", "pll_src",
            "pll_phy_ref";
    assigned-clocks = <&clk 107>,
        <&clk 109>,
        <&clk 266>;
    assigned-clock-parents = <&clk 78>,
        <&clk 78>,
        <&clk 3>;
    assigned-clock-rates = <800000000>,
          <400000000>;
    status = "disabled";
   };
  };

  usb_dwc3_0: usb@38100000 {
   compatible = "fsl,imx8mq-dwc3", "snps,dwc3";
   reg = <0x38100000 0x10000>;
   clocks = <&clk 206>,
            <&clk 152>,
     <&clk 1>;
   clock-names = "bus_early", "ref", "suspend";
   assigned-clocks = <&clk 110>,
                     <&clk 152>;
   assigned-clock-parents = <&clk 86>,
                            <&clk 72>;
   assigned-clock-rates = <500000000>, <100000000>;
   interrupts = <0 40 4>;
   phys = <&usb3_phy0>, <&usb3_phy0>;
   phy-names = "usb2-phy", "usb3-phy";
   power-domains = <&pgc_otg1>;
   snps,parkmode-disable-ss-quirk;
   snps,dis_rxdet_inp3_quirk;
   status = "disabled";
  };

  usb3_phy0: usb-phy@381f0040 {
   compatible = "fsl,imx8mq-usb-phy";
   reg = <0x381f0040 0x40>;
   clocks = <&clk 208>;
   clock-names = "phy";
   assigned-clocks = <&clk 153>;
   assigned-clock-parents = <&clk 72>;
   assigned-clock-rates = <100000000>;
   #phy-cells = <0>;
   status = "disabled";
  };

  usb_dwc3_1: usb@38200000 {
   compatible = "fsl,imx8mq-dwc3", "snps,dwc3";
   reg = <0x38200000 0x10000>;
   clocks = <&clk 207>,
            <&clk 152>,
     <&clk 1>;
   clock-names = "bus_early", "ref", "suspend";
   assigned-clocks = <&clk 110>,
                     <&clk 152>;
   assigned-clock-parents = <&clk 86>,
                            <&clk 72>;
   assigned-clock-rates = <500000000>, <100000000>;
   interrupts = <0 41 4>;
   phys = <&usb3_phy1>, <&usb3_phy1>;
   phy-names = "usb2-phy", "usb3-phy";
   power-domains = <&pgc_otg2>;
   snps,parkmode-disable-ss-quirk;
   snps,dis_rxdet_inp3_quirk;
   status = "disabled";
  };

  usb3_phy1: usb-phy@382f0040 {
   compatible = "fsl,imx8mq-usb-phy";
   reg = <0x382f0040 0x40>;
   clocks = <&clk 209>;
   clock-names = "phy";
   assigned-clocks = <&clk 153>;
   assigned-clock-parents = <&clk 72>;
   assigned-clock-rates = <100000000>;
   #phy-cells = <0>;
   status = "disabled";
  };

  dma_apbh: dma-apbh@33000000 {
   compatible = "fsl,imx7d-dma-apbh", "fsl,imx28-dma-apbh";
   reg = <0x33000000 0x2000>;
   interrupts = <0 12 4>,
         <0 12 4>,
         <0 12 4>,
         <0 12 4>;
   interrupt-names = "gpmi0", "gpmi1", "gpmi2", "gpmi3";
   #dma-cells = <1>;
   dma-channels = <4>;
   clocks = <&clk 256>;
  };

  gpmi: gpmi-nand@33002000{
   compatible = "fsl,imx7d-gpmi-nand";
   #address-cells = <1>;
   #size-cells = <1>;
   reg = <0x33002000 0x2000>, <0x33004000 0x4000>;
   reg-names = "gpmi-nand", "bch";
   interrupts = <0 14 4>;
   interrupt-names = "bch";
   clocks = <&clk 226>,
    <&clk 256>;
   clock-names = "gpmi_io", "gpmi_bch_apb";
   dmas = <&dma_apbh 0>;
   dma-names = "rx-tx";
   status = "disabled";
  };

  pcie0: pcie@33800000 {
   compatible = "fsl,imx8mq-pcie";
   reg = <0x33800000 0x400000>,
         <0x1ff00000 0x80000>;
   reg-names = "dbi", "config";
   #address-cells = <3>;
   #size-cells = <2>;
   device_type = "pci";
   bus-range = <0x00 0xff>;
   ranges = <0x81000000 0 0x00000000 0x1ff80000 0 0x00010000>,
     <0x82000000 0 0x18000000 0x18000000 0 0x07f00000>;
   num-lanes = <1>;
   interrupts = <0 122 4>;
   interrupt-names = "msi";
   #interrupt-cells = <1>;
   interrupt-map-mask = <0 0 0 0x7>;
   interrupt-map = <0 0 0 1 &gic 0 125 4>,
                   <0 0 0 2 &gic 0 124 4>,
                   <0 0 0 3 &gic 0 123 4>,
                   <0 0 0 4 &gic 0 122 4>;
   fsl,max-link-speed = <2>;
   linux,pci-domain = <0>;
   power-domains = <&pgc_pcie>;
   resets = <&src 26>,
            <&src 28>,
            <&src 29>;
   reset-names = "pciephy", "apps", "turnoff";
   assigned-clocks = <&clk 124>,
                     <&clk 125>,
                     <&clk 126>;
   assigned-clock-parents = <&clk 84>,
                            <&clk 80>,
                            <&clk 71>;
   assigned-clock-rates = <250000000>, <100000000>,
                          <10000000>;
   status = "disabled";
  };

  pcie1: pcie@33c00000 {
   compatible = "fsl,imx8mq-pcie";
   reg = <0x33c00000 0x400000>,
         <0x27f00000 0x80000>;
   reg-names = "dbi", "config";
   #address-cells = <3>;
   #size-cells = <2>;
   device_type = "pci";
   ranges = <0x81000000 0 0x00000000 0x27f80000 0 0x00010000>,
      <0x82000000 0 0x20000000 0x20000000 0 0x07f00000>;
   num-lanes = <1>;
   interrupts = <0 74 4>;
   interrupt-names = "msi";
   #interrupt-cells = <1>;
   interrupt-map-mask = <0 0 0 0x7>;
   interrupt-map = <0 0 0 1 &gic 0 77 4>,
     <0 0 0 2 &gic 0 76 4>,
     <0 0 0 3 &gic 0 75 4>,
     <0 0 0 4 &gic 0 74 4>;
   fsl,max-link-speed = <2>;
   linux,pci-domain = <1>;
   power-domains = <&pgc_pcie>;
   resets = <&src 34>,
            <&src 36>,
            <&src 37>;
   reset-names = "pciephy", "apps", "turnoff";
   assigned-clocks = <&clk 173>,
                     <&clk 174>,
                     <&clk 175>;
   assigned-clock-parents = <&clk 84>,
                            <&clk 80>,
                            <&clk 71>;
   assigned-clock-rates = <250000000>, <100000000>,
                          <10000000>;
   status = "disabled";
  };

  pcie1_ep: pcie_ep@33c00000 {
   compatible = "fsl,imx8mq-pcie-ep";
   reg = <0x33c00000 0x000400000>,
         <0x20000000 0x08000000>;
   reg-names = "regs", "addr_space";
   num-lanes = <1>;
   interrupts = <0 80 4>;
   interrupt-names = "dma";
   fsl,max-link-speed = <2>;
   power-domains = <&pgc_pcie>;
   resets = <&src 34>,
     <&src 36>,
     <&src 37>;
   reset-names = "pciephy", "apps", "turnoff";
   num-ib-windows = <4>;
   num-ob-windows = <4>;
   status = "disabled";
  };

  gic: interrupt-controller@38800000 {
   compatible = "arm,gic-v3";
   reg = <0x38800000 0x10000>,
         <0x38880000 0xc0000>,
         <0x31000000 0x2000>,
         <0x31010000 0x2000>,
         <0x31020000 0x2000>;
   #interrupt-cells = <3>;
   interrupt-controller;
   interrupts = <1 9 4>;
   interrupt-parent = <&gic>;
  };

  ddr-pmu@3d800000 {
   compatible = "fsl,imx8mq-ddr-pmu", "fsl,imx8m-ddr-pmu";
   reg = <0x3d800000 0x400000>;
   interrupt-parent = <&gic>;
   interrupts = <0 98 4>;
  };

  vpu: vpu@38300000 {
   compatible = "nxp,imx8mq-hantro";
   reg = <0x38300000 0x200000>;
   reg-names = "regs_hantro";
   interrupts = <0 7 4>, <0 8 4>;
   interrupt-names = "irq_hantro_g1", "irq_hantro_g2";
   clocks = <&clk 229>, <&clk 230>, <&clk 223>;
   clock-names = "clk_hantro_g1", "clk_hantro_g2", "clk_hantro_bus";
   assigned-clocks = <&clk 120>, <&clk 121>, <&clk 106>;
   assigned-clock-parents = <&clk 22>, <&clk 22>, <&clk 78>;
   assigned-clock-rates = <600000000>, <600000000>, <800000000>;
   power-domains = <&pgc_vpu>;
   status = "disabled";
  };

  vpu_v4l2: vpu_v4l2 {
   compatible = "nxp,imx8m-vsiv4l2";
   status = "disabled";
  };
 };

 gpu3d: gpu3d@38000000 {
  compatible = "fsl,imx8mq-gpu", "fsl,imx6q-gpu";
  reg = <0x0 0x38000000 0x0 0x40000>, <0x0 0x40000000 0x0 0xC0000000>, <0x0 0x0 0x0 0x10000000>;
  reg-names = "iobase_3d", "phys_baseaddr", "contiguous_mem";
  interrupts = <0 3 4>;
  interrupt-names = "irq_3d";
  clocks = <&clk 215>,
    <&clk 102>,
    <&clk 111>,
    <&clk 112>;
  clock-names = "gpu3d_clk", "gpu3d_shader_clk", "gpu3d_axi_clk", "gpu3d_ahb_clk";
  assigned-clocks = <&clk 97>,
    <&clk 100>,
    <&clk 111>,
    <&clk 112>;
  assigned-clock-parents = <&clk 17>,
    <&clk 17>,
    <&clk 17>,
    <&clk 17>;
  assigned-clock-rates = <800000000>, <800000000>, <800000000>, <800000000>;
  power-domains = <&pgc_gpu>;
  status = "disabled";
 };
};
# 10 "tmp/linux-imx/arch/arm64/boot/dts/freescale/maaxboard.dts" 2

/ {
 model = "Avnet MaaXBoard";
 compatible = "avnet,maaxboard", "fsl,imx8mq";

 chosen {
  stdout-path = &uart1;
 };

 memory@40000000 {
  device_type = "memory";
  reg = <0x00000000 0x40000000 0 0x40000000>;
 };

 resmem: reserved-memory {
  #address-cells = <2>;
  #size-cells = <2>;
  ranges;


  linux,cma {
   compatible = "shared-dma-pool";
   reusable;
   size = <0 0x3c000000>;
   alloc-ranges = <0 0x40000000 0 0x40000000>;
   linux,cma-default;
  };
 };

 pmic_osc: clock-pmic {
        compatible = "fixed-clock";
        #clock-cells = <0>;
        clock-frequency = <32768>;
        clock-output-names = "pmic_osc";
    };

    leds {
        compatible = "gpio-leds";
        pinctrl-names = "default";
        pinctrl-0 = <&pinctrl_gpio_leds>;
        status = "okay";

        sys_led {
            label = "sys_led";
            gpios = <&gpio1 5 0>;
            default-state = "on";
            linux,default-trigger = "heartbeat";
        };

        usr_led {
            label = "usr_led";
            gpios = <&gpio1 8 0>;
            default-state = "on";
        };

    };

    gpio_keys {
        compatible = "gpio-keys";
        pinctrl-names = "default";
        pinctrl-0 = <&pinctrl_gpio_keys>;

        home {
            label = "home Button";
            gpios = <&gpio3 7 1>;
            linux,code = <102>;
            gpio-key,wakeup;
        };

        back {
            label = "back Button";
            gpios = <&gpio3 6 1>;
            linux,code = <0x19c>;
        };
    };

    regulators {
        compatible = "simple-bus";
        #address-cells = <1>;
        #size-cells = <0>;

        reg_usb1_en: regulator-usb1-vcc {
            compatible = "regulator-fixed";
            pinctrl-names = "default";
            pinctrl-0 = <&pinctrl_usb1_pwr_en>;
            regulator-name = "usb1_pwr_en";
            regulator-min-microvolt = <3300000>;
            regulator-max-microvolt = <3300000>;
            enable-active-high;
            regulator-always-on;
            regulator-boot-on;
            startup-delay-us = <160000>;
            gpio = <&gpio1 12 1>;
        };

        reg_3V3WF: regulator@1 {
            compatible = "regulator-fixed";
            reg = <1>;
            pinctrl-names = "default";
            pinctrl-0 = <&pinctrl_reg3V3wf>;
            regulator-name = "WF_3V3";
            regulator-min-microvolt = <3300000>;
            regulator-max-microvolt = <3300000>;
            gpio = <&gpio2 20 0>;
            regulator-always-on;
            enable-active-high;
        };
 };

    wlan_pwrseq: sdio-pwrseq {
        compatible = "mmc-pwrseq-simple";
        pinctrl-names = "default";
        pinctrl-0 = <&pinctrl_wlan>;
        reset-gpios = <&gpio2 19 1>;
    };

    bt_reset: bt_reset{
        compatible = "gpio-reset";
        reset-gpios = <&gpio5 11 1>;
        reset-delay-us = <1000>;
        reset-post-delay-ms = <40>;
        #reset-cells = <0>;
    };

    hdmi_audio: sound-hdmi {
        compatible = "fsl,imx-audio-hdmi";
        model = "imx-audio-hdmi";
        audio-cpu = <&sai4>;
        protocol = <1>;
        hdmi-out;
        constraint-rate = <44100>,
                <88200>,
                <176400>,
                <32000>,
                <48000>,
                <96000>,
                <192000>;
        status = "disabled";
    };

    backlight: pwm-backlight {
            compatible = "pwm-backlight";
            pwms = <&pwm1 0 40000 0>;
            brightness-levels = <0 8 32 64 96 128 160 192 224 255>;
            default-brightness-level = <8>;
            enable-pwm-on;
            status = "disabled";
    };
};

&A53_0 {
 cpu-supply = <&buck2_reg>;
};

&A53_1 {
 cpu-supply = <&buck2_reg>;
};

&A53_2 {
 cpu-supply = <&buck2_reg>;
};

&A53_3 {
 cpu-supply = <&buck2_reg>;
};


&fec1 {
 pinctrl-names = "default";
 pinctrl-0 = <&pinctrl_fec1>;
 phy-mode = "rgmii-id";
 phy-handle = <&ethphy0>;
 fsl,magic-packet;
 phy-reset-gpios = <&gpio1 9 1>;
 status = "okay";

 mdio {
  #address-cells = <1>;
  #size-cells = <0>;

  ethphy0: ethernet-phy@0 {
   compatible = "ethernet-phy-ieee802.3-c22";
   reg = <4>;
   at803x,eee-disabled;
  };
 };
};

&i2c1 {
    clock-frequency = <100000>;
    pinctrl-names = "default";
    pinctrl-0 = <&pinctrl_i2c1>;
    status = "okay";

    pmic: pmic@4b {
        compatible = "rohm,bd71837";
        reg = <0x4b>;
        pinctrl-names = "default";
        pinctrl-0 = <&pinctrl_pmic>;
        clocks = <&pmic_osc>;
        clock-names = "osc";
        clock-output-names = "pmic_clk";
        interrupt-parent = <&gpio1>;
        interrupts = <7 1>;
        interrupt-names = "irq";
        rohm,reset-snvs-powered;

        regulators {
            buck1_reg: BUCK1 {
                regulator-name = "buck1";
                regulator-min-microvolt = <700000>;
                regulator-max-microvolt = <1300000>;
                regulator-boot-on;
                regulator-always-on;
                regulator-ramp-delay = <1250>;
                rohm,dvs-run-voltage = <900000>;
                rohm,dvs-idle-voltage = <850000>;
                rohm,dvs-suspend-voltage = <800000>;
            };

            buck2_reg: BUCK2 {
                regulator-name = "buck2";
                regulator-min-microvolt = <700000>;
                regulator-max-microvolt = <1300000>;
                regulator-boot-on;
                regulator-always-on;
                regulator-ramp-delay = <1250>;
                rohm,dvs-run-voltage = <1000000>;
                rohm,dvs-idle-voltage = <900000>;
            };

            buck3_reg: BUCK3 {
                regulator-name = "buck3";
                regulator-min-microvolt = <700000>;
                regulator-max-microvolt = <1300000>;
                regulator-boot-on;
                rohm,dvs-run-voltage = <1000000>;
                regulator-enable-ramp-delay= <180>;
            };

            buck4_reg: BUCK4 {
                regulator-name = "buck4";
                regulator-min-microvolt = <700000>;
                regulator-max-microvolt = <1300000>;
                rohm,dvs-run-voltage = <1000000>;
                regulator-boot-on;
                regulator-enable-ramp-delay= <180>;
            };

            buck5_reg: BUCK5 {
                regulator-name = "buck5";
                regulator-min-microvolt = <900000>;
                regulator-max-microvolt = <1000000>;
                regulator-boot-on;
                regulator-always-on;
            };

            buck6_reg: BUCK6 {
                regulator-name = "buck6";
                regulator-min-microvolt = <3000000>;
                regulator-max-microvolt = <3300000>;
                regulator-boot-on;
                regulator-always-on;
            };

            buck7_reg: BUCK7 {
                regulator-name = "buck7";
                regulator-min-microvolt = <1800000>;
                regulator-max-microvolt = <1900000>;
                regulator-boot-on;
                regulator-always-on;
            };

            buck8_reg: BUCK8 {
                regulator-name = "buck8";
                regulator-min-microvolt = <1200000>;
                regulator-max-microvolt = <1300000>;
                regulator-boot-on;
                regulator-always-on;
            };

            ldo1_reg: LDO1 {
                regulator-name = "ldo1";
                regulator-min-microvolt = <3000000>;
                regulator-max-microvolt = <3300000>;
                regulator-boot-on;
                regulator-always-on;
            };

            ldo2_reg: LDO2 {
                regulator-name = "ldo2";
                regulator-min-microvolt = <900000>;
                regulator-max-microvolt = <900000>;
                regulator-boot-on;
                regulator-always-on;
            };

            ldo3_reg: LDO3 {
                regulator-name = "ldo3";
                regulator-min-microvolt = <1800000>;
                regulator-max-microvolt = <1900000>;
                regulator-boot-on;
                regulator-always-on;
            };

            ldo4_reg: LDO4 {
                regulator-name = "ldo4";
                regulator-min-microvolt = <900000>;
                regulator-max-microvolt = <1000000>;
                regulator-boot-on;
                regulator-always-on;
            };

            ldo5_reg: LDO5 {
                regulator-name = "ldo5";
                regulator-min-microvolt = <2500000>;
                regulator-max-microvolt = <2600000>;
                regulator-boot-on;
                regulator-always-on;
            };

            ldo6_reg: LDO6 {
                regulator-name = "ldo6";
                regulator-min-microvolt = <900000>;
                regulator-max-microvolt = <1000000>;
                regulator-boot-on;
                regulator-always-on;
            };

            ldo7_reg: LDO7 {
                regulator-name = "ldo7";
                regulator-min-microvolt = <3000000>;
                regulator-max-microvolt = <3300000>;
                regulator-boot-on;
                regulator-always-on;
            };
        };
    };
};

&pgc_gpu {
 power-supply = <&buck3_reg>;
};

&pgc_vpu {
 power-supply = <&buck4_reg>;
};

&snvs_pwrkey {
 status = "okay";
};

&uart1 {
 pinctrl-names = "default";
 pinctrl-0 = <&pinctrl_uart1>;
 assigned-clocks = <&clk 148>;
 assigned-clock-parents = <&clk 2>;
 status = "okay";
};


&usdhc1 {
 pinctrl-names = "default", "state_100mhz", "state_200mhz";
 pinctrl-0 = <&pinctrl_usdhc1>;
 pinctrl-1 = <&pinctrl_usdhc1_100mhz>;
 pinctrl-2 = <&pinctrl_usdhc1_200mhz>;
 bus-width = <8>;
 non-removable;
 no-sdio;
    no-1-8-v;
 status = "okay";
};


&usdhc2 {
    pinctrl-names = "default";
    pinctrl-0 = <&pinctrl_usdhc2>;
    bus-width = <4>;
    vmmc-supply = <&reg_3V3WF>;
    mmc-pwrseq = <&wlan_pwrseq>;
    no-1-8-v;
    non-removable;
    pm-ignore-notify;
    keep-power-in-suspend;
    status = "okay";

    #address-cells = <1>;
    #size-cells = <0>;
    brcmf: bcrmf@1 {
            reg = <1>;
            compatible = "brcm,bcm4329-fmac";
            interrupt-parent = <&gpio2>;
            interrupts = <12 8>;
            interrupt-names = "host-wake";
        };
};


&uart4 {
    pinctrl-names = "default";
    pinctrl-0 = <&pinctrl_uart4>;
    assigned-clocks = <&clk 151>;
    assigned-clock-parents = <&clk 71>;
    fsl,uart-has-rtscts;
    resets = <&bt_reset>;
    status = "okay";
};

&usb3_phy0 {
 status = "okay";
};

&usb_dwc3_0 {
 dr_mode = "host";
 status = "okay";
};

&usb3_phy1 {
 status = "okay";
};

&usb_dwc3_1 {
 dr_mode = "host";
 status = "okay";
};


&sai4 {
    assigned-clocks = <&clk 132>;
    assigned-clock-parents = <&clk 27>;
    assigned-clock-rates = <24576000>;
    clocks = <&clk 241>, <&clk 0>,
        <&clk 199>, <&clk 0>,
        <&clk 0>, <&clk 27>,
        <&clk 32>;
    clock-names = "bus", "mclk0", "mclk1", "mclk2", "mclk3", "pll8k", "pll11k";
    status = "disabled";
};

&dphy {
    status = "okay";
};

&dcss {
    status = "disabled";
};

&hdmi {
    compatible = "cdn,imx8mq-hdmi";
    lane-mapping = <0xe4>;
    status = "disabled";
};



&pwm1 {
        pinctrl-names = "default";
        pinctrl-0 = <&pinctrl_pwm1>;

        status = "okay";
};

&i2c4 {
    clock-frequency = <400000>;
    pinctrl-names = "default";
    pinctrl-0 = <&pinctrl_i2c4>;
    status = "disabled";

    ft5426: ft5426_ts@38 {
        compatible = "focaltech,fts";
        reg = <0x38>;
        pinctrl-0 = <&pinctrl_ts>;
        interrupt-parent = <&gpio3>;
        interrupts = <13 2>;
        focaltech,reset-gpio = <&gpio1 4 0x01>;
        focaltech,irq-gpio = <&gpio3 13 0x02>;
        focaltech,max-touch-number = <10>;
        focaltech,panel-type = <0x54260002>;
        focaltech,display-coords = <0 0 720 1280>;
        focaltech,have-key;
        focaltech,key-number = <3>;
        focaltech,keys = <139 102 158>;
        focaltech,key-y-coord = <2000>;
        focaltech,key-x-coords = <200 600 800>;
        status = "disabled";
    };

    gt911: gt911_ts@14 {
        compatible = "goodix,gt911";
        reg = <0x14>;
        pinctrl-names = "default";
        pinctrl-0 = <&pinctrl_ts>;
        interrupt-parent = <&gpio3>;
        interrupts = <13 2>;
        irq-gpios = <&gpio3 13 0>;
        reset-gpios = <&gpio1 4 0>;
        touchscreen-size-x = <720>;
        touchscreen-size-y = <1280>;
        status = "disabled";
    };
};


&csi1_bridge {
    fsl,mipi-mode;
    fsl,two-8bit-sensor-mode;
    status = "disabled";

    port {
        csi1_ep: endpoint {
            remote-endpoint = <&csi1_mipi_ep>;
        };
    };
};

&mipi_csi_1 {
    #address-cells = <1>;
    #size-cells = <0>;
    status = "disabled";
    port {
        csi1_mipi_ep: endpoint@1 {
            remote-endpoint = <&csi1_ep>;
        };
    };
};

&wdog1 {
 pinctrl-names = "default";
 pinctrl-0 = <&pinctrl_wdog>;
 fsl,ext-reset-output;
 status = "okay";
};

&iomuxc {
 pinctrl-names = "default";

 pinctrl_ir_recv: ir-recv {
  fsl,pins = <
   0x058 0x2C0 0x000 0x0 0x0 0x4f
  >;
 };

 pinctrl_pmic: pmicirq {
        fsl,pins = <
            0x044 0x2AC 0x000 0x0 0x0 0x19
        >;
    };

    pinctrl_fec1: fec1grp {
  fsl,pins = <
   0x068 0x2D0 0x000 0x0 0x0 0x3
   0x06C 0x2D4 0x4C0 0x0 0x1 0x23
   0x070 0x2D8 0x000 0x0 0x0 0x1f
   0x074 0x2DC 0x000 0x0 0x0 0x1f
   0x078 0x2E0 0x000 0x0 0x0 0x1f
   0x07C 0x2E4 0x000 0x0 0x0 0x1f
   0x09C 0x304 0x000 0x0 0x0 0x91
   0x098 0x300 0x000 0x0 0x0 0x91
   0x094 0x2FC 0x000 0x0 0x0 0x91
   0x090 0x2F8 0x000 0x0 0x0 0x91
   0x084 0x2EC 0x000 0x0 0x0 0x1f
   0x08C 0x2F4 0x000 0x0 0x0 0x91
   0x088 0x2F0 0x000 0x0 0x0 0x91
   0x080 0x2E8 0x000 0x0 0x0 0x1f
   0x04C 0x2B4 0x000 0x0 0x0 0x19
  >;
 };

 pinctrl_i2c1: i2c1grp {
  fsl,pins = <
   0x214 0x47C 0x000 0x0 0x0 0x4000007f
   0x218 0x480 0x000 0x0 0x0 0x4000007f
  >;
 };

 pinctrl_uart1: uart1grp {
  fsl,pins = <
   0x234 0x49C 0x4F4 0x0 0x0 0x49
   0x238 0x4A0 0x000 0x0 0x0 0x49
  >;
 };

 pinctrl_usdhc1: usdhc1grp {
  fsl,pins = <
   0x0A0 0x308 0x000 0x0 0x0 0x83
   0x0A4 0x30C 0x000 0x0 0x0 0xc3
   0x0A8 0x310 0x000 0x0 0x0 0xc3
   0x0AC 0x314 0x000 0x0 0x0 0xc3
   0x0B0 0x318 0x000 0x0 0x0 0xc3
   0x0B4 0x31C 0x000 0x0 0x0 0xc3
   0x0B8 0x320 0x000 0x0 0x0 0xc3
   0x0BC 0x324 0x000 0x0 0x0 0xc3
   0x0C0 0x328 0x000 0x0 0x0 0xc3
   0x0C4 0x32C 0x000 0x0 0x0 0xc3
   0x0CC 0x334 0x000 0x0 0x0 0x83
   0x0C8 0x330 0x000 0x0 0x0 0xc1
  >;
 };

 pinctrl_usdhc1_100mhz: usdhc1-100grp {
  fsl,pins = <
   0x0A0 0x308 0x000 0x0 0x0 0x8d
   0x0A4 0x30C 0x000 0x0 0x0 0xcd
   0x0A8 0x310 0x000 0x0 0x0 0xcd
   0x0AC 0x314 0x000 0x0 0x0 0xcd
   0x0B0 0x318 0x000 0x0 0x0 0xcd
   0x0B4 0x31C 0x000 0x0 0x0 0xcd
   0x0B8 0x320 0x000 0x0 0x0 0xcd
   0x0BC 0x324 0x000 0x0 0x0 0xcd
   0x0C0 0x328 0x000 0x0 0x0 0xcd
   0x0C4 0x32C 0x000 0x0 0x0 0xcd
   0x0CC 0x334 0x000 0x0 0x0 0x8d
   0x0C8 0x330 0x000 0x0 0x0 0xc1
  >;
 };

 pinctrl_usdhc1_200mhz: usdhc1-200grp {
  fsl,pins = <
   0x0A0 0x308 0x000 0x0 0x0 0x9f
   0x0A4 0x30C 0x000 0x0 0x0 0xdf
   0x0A8 0x310 0x000 0x0 0x0 0xdf
   0x0AC 0x314 0x000 0x0 0x0 0xdf
   0x0B0 0x318 0x000 0x0 0x0 0xdf
   0x0B4 0x31C 0x000 0x0 0x0 0xdf
   0x0B8 0x320 0x000 0x0 0x0 0xdf
   0x0BC 0x324 0x000 0x0 0x0 0xdf
   0x0C0 0x328 0x000 0x0 0x0 0xdf
   0x0C4 0x32C 0x000 0x0 0x0 0xdf
   0x0CC 0x334 0x000 0x0 0x0 0x9f
   0x0C8 0x330 0x000 0x0 0x0 0xc1
  >;
 };

    pinctrl_gpio_leds: gpio_ledsgrp {
        fsl,pins = <
            0x03C 0x2A4 0x000 0x0 0x0 0x19
            0x048 0x2B0 0x000 0x0 0x0 0x19
        >;
    };

    pinctrl_gpio_keys: gpio_keysgrp {
        fsl,pins = <
            0x110 0x378 0x000 0x5 0x0 0x56
            0x10C 0x374 0x000 0x5 0x0 0x56
        >;
    };

    pinctrl_usb1_pwr_en: usb1_pwr_en {
        fsl,pins = <
            0x058 0x2C0 0x000 0x0 0x0 0x16
        >;
    };

    pinctrl_usdhc2: usdhc2grp {
        fsl,pins = <
            0x0D4 0x33C 0x000 0x0 0x0 0x83
            0x0D8 0x340 0x000 0x0 0x0 0xc3
            0x0DC 0x344 0x000 0x0 0x0 0xc3
            0x0E0 0x348 0x000 0x0 0x0 0xc3
            0x0E4 0x34C 0x000 0x0 0x0 0xc3
            0x0E8 0x350 0x000 0x0 0x0 0xc3
        >;
    };

    pinctrl_wlan: wlangrp {
        fsl,pins = <
            0x0EC 0x354 0x000 0x5 0x0 0x19
            0x0D0 0x338 0x000 0x5 0x0 0x19
            0x028 0x290 0x000 0x5 0x0 0x05
        >;
    };

    pinctrl_reg3V3wf: reg3V3wfgrp {
        fsl,pins = <
            0x0F0 0x358 0x000 0x5 0x0 0x19
        >;
    };

    pinctrl_uart4: uart4grp {
        fsl,pins = <
            0x24C 0x4B4 0x50C 0x0 0x2 0x49
            0x250 0x4B8 0x000 0x0 0x0 0x49
            0x210 0x478 0x508 0x1 0x1 0x49
            0x20C 0x474 0x000 0x1 0x0 0x49
            0x208 0x470 0x000 0x5 0x0 0x19
        >;
    };

    pinctrl_pwm1: pwm1_grp {
        fsl,pins = <
            0x02C 0x294 0x000 0x1 0x0 0x06
        >;
    };

    pinctrl_ts: ts_pinsgrp {
        fsl,pins = <
            0x128 0x390 0x000 0x5 0x0 0x19
            0x038 0x2A0 0x000 0x0 0x0 0x19
        >;
    };

    pinctrl_i2c4: i2c4grp {
        fsl,pins = <
            0x22C 0x494 0x000 0x0 0x0 0x4000007f
            0x230 0x498 0x000 0x0 0x0 0x4000007f
        >;
    };

    pinctrl_csi1: csi1grp {
        fsl,pins = <
            0x13C 0x3A4 0x000 0x5 0x0 0x19
            0x12C 0x394 0x000 0x5 0x0 0x19
        >;
    };

 pinctrl_wdog: wdog1grp {
  fsl,pins = <
   0x030 0x298 0x000 0x1 0x0 0xc6
  >;
 };
};

&vpu {
 status = "okay";
};

&gpu3d {
 status = "okay";
};

&irqsteer {
 status = "okay";
};

&tmu {
    throttle-cfgs {
        throttle_devfreq: devfreq {
            throttle,max_state = <2>;
            #cooling-cells = <2>;
        };
    };
};

&{/thermal-zones} {
    cpu-thermal {
        polling-delay-passive = <250>;
        polling-delay = <2000>;
        thermal-sensors = <&tmu 0>;

        trips {
            cpu_alert0: trip0 {
                temperature = <80000>;
                hysteresis = <2000>;
                type = "passive";
            };
            cpu_alert1: trip1 {
                temperature = <85000>;
                hysteresis = <2000>;
                type = "passive";
            };
            cpu-crit {
                temperature = <95000>;
                hysteresis = <2000>;
                type = "critical";
            };
        };

        cooling-maps {
            map0 {
                trip = <&cpu_alert0>;
                cooling-device =
                    <&throttle_devfreq 0 1>,
                    <&A53_0 (~0) (~0)>,
                    <&A53_1 (~0) (~0)>,
                    <&A53_2 (~0) (~0)>,
                    <&A53_3 (~0) (~0)>;
            };
            map1 {
                trip = <&cpu_alert1>;
                cooling-device =
                    <&throttle_devfreq 0 2>;
            };
        };
    };
};
